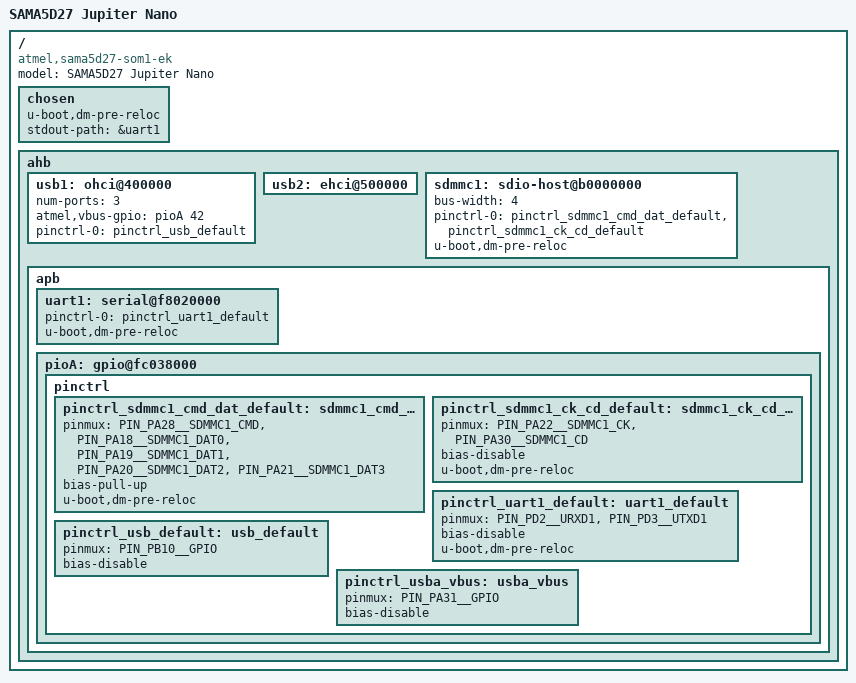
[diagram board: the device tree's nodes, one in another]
/*
 * at91-sama5d27_jupiter_nano.dts - Device Tree file for SAMA5D27
 * 									 Jupiter Nano board
 *
 * Contributed and maintained by: Shashank Kulkarni 
 * 
 * Jupiter Nano is an open-source hardware based on Microchip SAMA7D27
 * 1 Gbit LPDDR2 SiP device. This board is designed by Starcat.io.
 *
 * This DTS is redcued derivative of at91-sama5d27_som1_ek.dts.
 *
 * Copyright (C) 2017 Microchip Corporation
 *		      Wenyou Yang <wenyou.yang@microchip.com>
 */
/dts-v1/;
#include <dt-bindings/gpio/gpio.h>
#include "sama5d27_som1.dtsi"

/ {
	model = "SAMA5D27 Jupiter Nano";
	compatible = "atmel,sama5d27-som1-ek", "atmel,sama5d2", "atmel,sama5";

	chosen {
		u-boot,dm-pre-reloc;
		stdout-path = &uart1;
	};

	ahb {
		usb1: ohci@400000 {
			num-ports = <3>;
			atmel,vbus-gpio = <&pioA 42 0>;
			pinctrl-names = "default";
			pinctrl-0 = <&pinctrl_usb_default>;
			status = "okay";
		};

		usb2: ehci@500000 {
			status = "okay";
		};

		sdmmc1: sdio-host@b0000000 {
			bus-width = <4>;
			pinctrl-names = "default";
			pinctrl-0 = <&pinctrl_sdmmc1_cmd_dat_default &pinctrl_sdmmc1_ck_cd_default>;
			status = "okay"; /* conflict with qspi0 */
			u-boot,dm-pre-reloc;
		};

		apb {
			uart1: serial@f8020000 {
				pinctrl-names = "default";
				pinctrl-0 = <&pinctrl_uart1_default>;
				status = "okay";
				u-boot,dm-pre-reloc;
			};

			pioA: gpio@fc038000 {
				pinctrl {
					pinctrl_sdmmc1_cmd_dat_default: sdmmc1_cmd_dat_default {
						pinmux = <PIN_PA28__SDMMC1_CMD>,
							 <PIN_PA18__SDMMC1_DAT0>,
							 <PIN_PA19__SDMMC1_DAT1>,
							 <PIN_PA20__SDMMC1_DAT2>,
							 <PIN_PA21__SDMMC1_DAT3>;
						bias-pull-up;
						u-boot,dm-pre-reloc;
					};

					pinctrl_sdmmc1_ck_cd_default: sdmmc1_ck_cd_default {
						pinmux = <PIN_PA22__SDMMC1_CK>,
							 <PIN_PA30__SDMMC1_CD>;
						bias-disable;
						u-boot,dm-pre-reloc;
					};

					pinctrl_uart1_default: uart1_default {
						pinmux = <PIN_PD2__URXD1>,
							 <PIN_PD3__UTXD1>;
						bias-disable;
						u-boot,dm-pre-reloc;
					};

					pinctrl_usb_default: usb_default {
						pinmux = <PIN_PB10__GPIO>;
						bias-disable;
					};

					pinctrl_usba_vbus: usba_vbus {
						pinmux = <PIN_PA31__GPIO>;
						bias-disable;
					};
				};
			};
		};
	};
};
